# ATSAM4LC2C register map
Vendor: Atmel Corporation; Series: SAM4L; File version: B
CPU: CM4 r0p1, little endian, MPU, no FPU, 4 interrupt priority bits
Registers are 32-bit, write-only, reset 0x0 unless marked. A register's access mark holds for its fields unless they carry their own. Offsets are from the block's base; [hi:lo] are bit positions; {n}, {i} and the like mark numbered series; 'fields as' and 'values as' point back to an identical list.

## SPI — Serial Peripheral Interface
Base 0x40008000; register names take the prefix SPI_
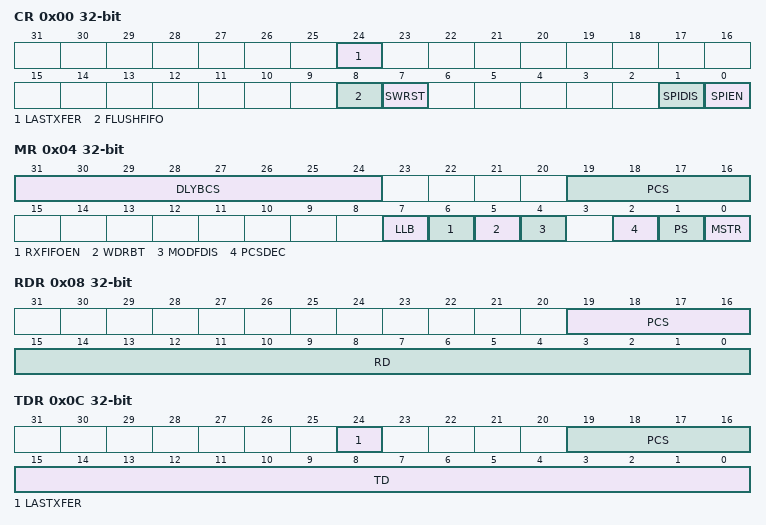
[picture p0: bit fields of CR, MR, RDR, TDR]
0x00 CR — Control Register
  [24] LASTXFER — Last Transfer
    0=No effect; 1=The current NPCS will be deasserted after the character written in TD has been transferred. When CSAAT is set, thisallows to close the communication with the current serial peripheral by raising the corresponding NPCS line as soon as TDtransfer has completed.
  [8] FLUSHFIFO — Flush FIFO command
  [7] SWRST — SPI Software Reset
    0=No effect; 1=Reset the SPI. A software-triggered hardware reset of the SPI interface is performed.
  [1] SPIDIS — SPI Disable
    0=No effect; 1=Disables the SPI.All pins are set in input mode and no data is received or transmitted.If a transfer is in progress, the transfer is finished before the SPI is disabled.If both SPIEN and SPIDIS are equal to one when the control register is written, the SPI is disabled
  [0] SPIEN — SPI Enable
    0=No effect; 1=Enables the SPI to transfer and receive data
0x04 MR rw — Mode Register
  [31:24] DLYBCS — Delay Between Chip Selects
  [19:16] PCS — Peripheral Chip Select
  [7] LLB — Local Loopback Enable
    0=Local loopback path disabled; 1=Local loopback path enabled.LLB controls the local loopback on the data serializer for testing in Master Mode only
  [6] RXFIFOEN — FIFO in Reception Enable
  [5] WDRBT — wait data read before transfer
  [4] MODFDIS — Mode Fault Detection
    0=Mode fault detection is enabled; 1=Mode fault detection is disabled
  [2] PCSDEC — Chip Select Decode
    0=The chip selects are directly connected to a peripheral device; 1=The four chip select lines are connected to a 4- to 16-bit decoder.When PCSDEC equals one, up to 15 Chip Select signals can be generated with the four lines using an external 4- to 16-bitdecoder. The Chip Select Registers define the characteristics of the 16 chip selects according to the following rules:CSR0 defines peripheral chip select signals 0 to 3.CSR1 defines peripheral chip select signals 4 to 7.CSR2 defines peripheral chip select signals 8 to 11.CSR3 defines peripheral chip select signals 12 to 15.
  [1] PS — Peripheral Select
    0=Fixed Peripheral Select; 1=Variable Peripheral Select
  [0] MSTR — Master/Slave Mode
    0=SPI is in Slave mode; 1=SPI is in Master mode
0x08 RDR ro — Receive Data Register
  [19:16] PCS — Peripheral Chip Select
  [15:0] RD — Receive Data
0x0C TDR — Transmit Data Register
  [24] LASTXFER — Last Transfer
    values as CR.LASTXFER
  [19:16] PCS — Peripheral Chip Select
  [15:0] TD — Transmit Data
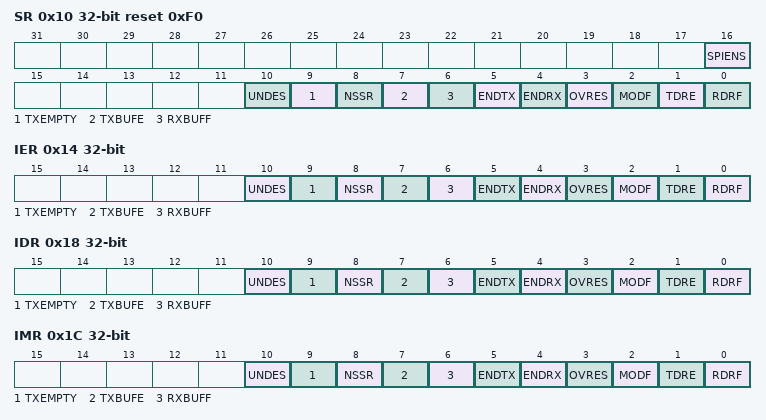
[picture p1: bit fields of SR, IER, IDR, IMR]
0x10 SR ro reset 0xF0 — Status Register
  [16] SPIENS — SPI Enable Status
    0=SPI is disabled; 1=SPI is enabled
  [10] UNDES — Underrun Error Status (Slave Mode Only)
  [9] TXEMPTY — Transmission Registers Empty
    0=As soon as data is written in TDR; 1=TDR and internal shifter are empty. If a transfer delay has been defined, TXEMPTY is set after the completion ofsuch delay.
  [8] NSSR — NSS Rising
    0=No rising edge detected on NSS pin since last read; 1=A rising edge occurred on NSS pin since last read
  [7] TXBUFE — TX Buffer Empty
    0=TCR or TNCR has a value other than 0; 1=Both TCR and TNCR has a value of 0
  [6] RXBUFF — RX Buffer Full
    0=RCR or RNCR has a value other than 0; 1=Both RCR and RNCR has a value of 0
  [5] ENDTX — End of TX buffer
    0=The Transmit Counter Register has not reached 0 since the last write in TCR or TNCR; 1=The Transmit Counter Register has reached 0 since the last write in TCR or TNCR
  [4] ENDRX — End of RX buffer
    0=The Receive Counter Register has not reached 0 since the last write in RCR or RNCR; 1=The Receive Counter Register has reached 0 since the last write in RCR or RNCR
  [3] OVRES — Overrun Error Status
    0=No overrun has been detected since the last read of SR; 1=An overrun has occurred since the last read of SR
  [2] MODF — Mode Fault Error
    0=No Mode Fault has been detected since the last read of SR; 1=A Mode Fault occurred since the last read of the SR
  [1] TDRE — Transmit Data Register Empty
    0=Data has been written to TDR and not yet transferred to the serializer; 1=The last data written in the Transmit Data Register has been transferred to the serializer.TDRE equals zero when the SPI is disabled or at reset. The SPI enable command sets this bit to one.
  [0] RDRF — Receive Data Register Full
    0=No data has been received since the last read of RDR; 1=Data has been received and the received data has been transferred from the serializer to RDR since the last readof RDR
0x14 IER — Interrupt Enable Register
  [10] UNDES — Underrun Error Interrupt Enable
  [9] TXEMPTY — Transmission Registers Empty Enable
    0=No effect; 1=Enables the corresponding interrupt
  [8] NSSR — NSS Rising Interrupt Enable
    0=No effect; 1=Enables the corresponding interrupt
  [7] TXBUFE — Transmit Buffer Empty Interrupt Enable
    0=No effect; 1=Enables the corresponding interrupt
  [6] RXBUFF — Receive Buffer Full Interrupt Enable
    0=No effect; 1=Enables the corresponding interrupt
  [5] ENDTX — End of Transmit Buffer Interrupt Enable
    0=No effect; 1=Enables the corresponding interrupt
  [4] ENDRX — End of Receive Buffer Interrupt Enable
    0=No effect; 1=Enables the corresponding interrupt
  [3] OVRES — Overrun Error Interrupt Enable
    0=No effect; 1=Enables the corresponding interrupt
  [2] MODF — Mode Fault Error Interrupt Enable
    0=No effect; 1=Enables the corresponding interrupt
  [1] TDRE — Transmit Data Register Empty Interrupt Enable
    0=No effect; 1=Enables the corresponding interrupt
  [0] RDRF — Receive Data Register Full Interrupt Enable
    0=No effect; 1=Enables the corresponding interrupt
0x18 IDR — Interrupt Disable Register
  [10] UNDES — Underrun Error Interrupt Disable
  [9] TXEMPTY — Transmission Registers Empty Disable
    0=No effect; 1=Disables the corresponding interrupt
  [8] NSSR — NSS Rising Interrupt Disable
    0=No effect; 1=Disables the corresponding interrupt
  [7] TXBUFE — Transmit Buffer Empty Interrupt Disable
    0=No effect; 1=Disables the corresponding interrupt
  [6] RXBUFF — Receive Buffer Full Interrupt Disable
    0=No effect; 1=Disables the corresponding interrupt
  [5] ENDTX — End of Transmit Buffer Interrupt Disable
    0=No effect; 1=Disables the corresponding interrupt
  [4] ENDRX — End of Receive Buffer Interrupt Disable
    0=No effect; 1=Disables the corresponding interrupt
  [3] OVRES — Overrun Error Interrupt Disable
    0=No effect; 1=Disables the corresponding interrupt
  [2] MODF — Mode Fault Error Interrupt Disable
    0=No effect; 1=Disables the corresponding interrupt
  [1] TDRE — Transmit Data Register Empty Interrupt Disable
    0=No effect; 1=Disables the corresponding interrupt
  [0] RDRF — Receive Data Register Full Interrupt Disable
    0=No effect; 1=Disables the corresponding interrupt
0x1C IMR ro — Interrupt Mask Register
  [10] UNDES — Underrun Error Interrupt Mask
  [9] TXEMPTY — Transmission Registers Empty Mask
    0=The corresponding interrupt is not enabled; 1=The corresponding interrupt is enabled
  [8] NSSR — NSS Rising Interrupt Mask
    values as TXEMPTY
  [7] TXBUFE — Transmit Buffer Empty Interrupt Mask
    values as TXEMPTY
  [6] RXBUFF — Receive Buffer Full Interrupt Mask
    values as TXEMPTY
  [5] ENDTX — End of Transmit Buffer Interrupt Mask
    values as TXEMPTY
  [4] ENDRX — End of Receive Buffer Interrupt Mask
    values as TXEMPTY
  [3] OVRES — Overrun Error Interrupt Mask
    values as TXEMPTY
  [2] MODF — Mode Fault Error Interrupt Mask
    values as TXEMPTY
  [1] TDRE — Transmit Data Register Empty Interrupt Mask
    values as TXEMPTY
  [0] RDRF — Receive Data Register Full Interrupt Mask
    values as TXEMPTY
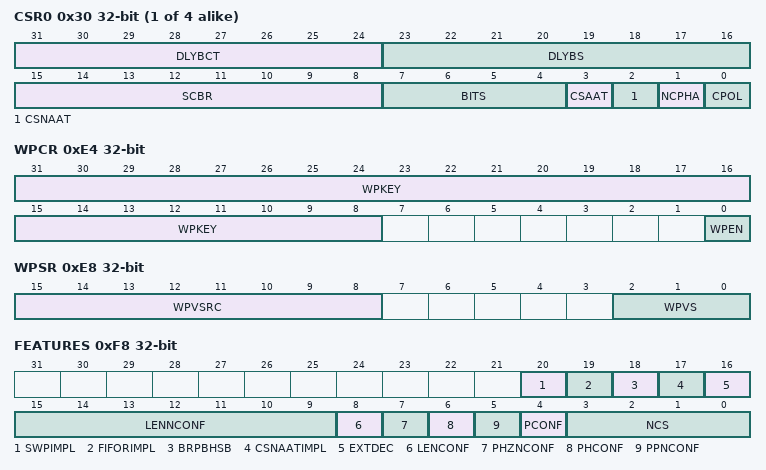
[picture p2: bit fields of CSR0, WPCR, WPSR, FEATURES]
{0x30+4i} CSR{i} (i=0..3) rw — Chip Select Register
  [31:24] DLYBCT — Delay Between Consecutive Transfers
  [23:16] DLYBS — Delay Before SPCK
  [15:8] SCBR — Serial Clock Baud Rate
  [7:4] BITS — Bits Per Transfer
    {v}={v+8}_BPT ({v+8} bits per transfer) (v=0..8)
  [3] CSAAT — Chip Select Active After Transfer
    0=The Peripheral Chip Select Line rises as soon as the last transfer is achieved; 1=The Peripheral Chip Select does not rise after the last transfer is achieved. It remains active until a new transfer isrequested on a different chip select.
  [2] CSNAAT — Chip Select Not Active After Transfer
  [1] NCPHA — Clock Phase
    0=Data is changed on the leading edge of SPCK and captured on the following edge of SPCK; 1=Data is captured on the leading edge of SPCK and changed on the following edge of SPCK.NCPHA determines which edge of SPCK causes data to change and which edge causes data to be captured. NCPHA isused with CPOL to produce the required clock/data relationship between master and slave devices.
  [0] CPOL — Clock Polarity
    0=The inactive state value of SPCK is logic level zero; 1=The inactive state value of SPCK is logic level one.CPOL is used to determine the inactive state value of the serial clock (SPCK). It is used with NCPHA to produce therequired clock/data relationship between master and slave devices.
0xE4 WPCR rw — Write Protection control Register
  [31:8] WPKEY — Write Protection Key Password
    0x535049=VALUE (SPI Write Protection Key Password)
  [0] WPEN — Write Protection Enable
0xE8 WPSR ro — Write Protection status Register
  [15:8] WPVSRC — Write Protection Violation Source
  [2:0] WPVS — Write Protection Violation Status
    1=WRITE_WITH_WP (The Write Protection has blocked a Write access to a protected register (since the last read).); 2=SWRST_WITH_WP (Software Reset has been performed while Write Protection was enabled (since the last read or since the last write access on MR, IER, IDR or CSRx).); 4=UNEXPECTED_WRITE (Write accesses have been detected on MR (while a chip select was active) or on CSRi (while the Chip Select "i" was active) since the last read.)
0xF8 FEATURES ro
  [20] SWPIMPL — Spurious Write Protection is Implemented
  [19] FIFORIMPL — FIFO in Reception is Implemented
  [18] BRPBHSB — Bridge Type is PB to HSB
  [17] CSNAATIMPL — CSNAAT Features are Implemented
  [16] EXTDEC — External Decoder is True
  [15:9] LENNCONF — Character Length if not Configurable
  [8] LENCONF — Character Length is Configurable
  [7] PHZNCONF — Phase is Zero if Phase is not Configurable
  [6] PHCONF — Phase is Configurable
  [5] PPNCONF — Polarity is Positive if Polarity is not Configurable
  [4] PCONF — Polarity is Configurable
  [3:0] NCS — Number of Chip Selects
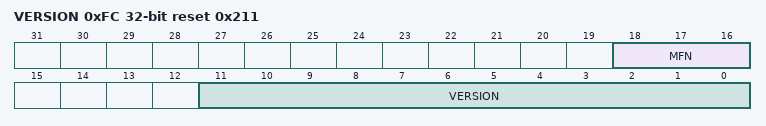
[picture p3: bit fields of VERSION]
0xFC VERSION ro reset 0x211
  [18:16] MFN, [11:0] VERSION

## Notices in the file
Atmel Microcontroller Software Support
Copyright (c) 2014, Atmel Corporation
All rights reserved.
Redistribution and use in source and binary forms, with or without
modification, are permitted provided that the following condition is met:
- Redistributions of source code must retain the above copyright notice,
this list of conditions and the disclaimer below.
Atmel's name may not be used to endorse or promote products derived from
this software without specific prior written permission.
DISCLAIMER: THIS SOFTWARE IS PROVIDED BY ATMEL "AS IS" AND ANY EXPRESS OR
IMPLIED WARRANTIES, INCLUDING, BUT NOT LIMITED TO, THE IMPLIED WARRANTIES OF
MERCHANTABILITY, FITNESS FOR A PARTICULAR PURPOSE AND NON-INFRINGEMENT ARE
DISCLAIMED. IN NO EVENT SHALL ATMEL BE LIABLE FOR ANY DIRECT, INDIRECT,
INCIDENTAL, SPECIAL, EXEMPLARY, OR CONSEQUENTIAL DAMAGES (INCLUDING, BUT NOT
LIMITED TO, PROCUREMENT OF SUBSTITUTE GOODS OR SERVICES; LOSS OF USE, DATA,
OR PROFITS; OR BUSINESS INTERRUPTION) HOWEVER CAUSED AND ON ANY THEORY OF
LIABILITY, WHETHER IN CONTRACT, STRICT LIABILITY, OR TORT (INCLUDING
NEGLIGENCE OR OTHERWISE) ARISING IN ANY WAY OUT OF THE USE OF THIS SOFTWARE,
EVEN IF ADVISED OF THE POSSIBILITY OF SUCH DAMAGE.
